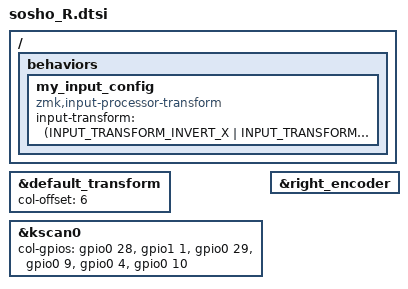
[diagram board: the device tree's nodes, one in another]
#include "sosho.dtsi"
#include <dt-bindings/zmk/input_transform.h>
#include <input/processors.dtsi>

&default_transform {
    col-offset = <6>;
};

&kscan0 {
    col-gpios
        = <&gpio0 28 GPIO_ACTIVE_HIGH>
        , <&gpio1 1  GPIO_ACTIVE_HIGH> 
        , <&gpio0 29 GPIO_ACTIVE_HIGH> 
        , <&gpio0 9  GPIO_ACTIVE_HIGH> 
        , <&gpio0 4  GPIO_ACTIVE_HIGH>
        , <&gpio0 10 GPIO_ACTIVE_HIGH>
        ;
};

&right_encoder{
    status =  "okay";
};

/ {
    behaviors {
        // オートマウスレイヤーの定義などに zip_xy_transform を適用
        my_input_config: my_input_config {
            compatible = "zmk,input-processor-transform";
            #input-processor-cells = <0>;
            // XとYの両方を反転させる場合は以下のように bitwise OR で指定
            input-transform = <(INPUT_TRANSFORM_INVERT_X | INPUT_TRANSFORM_INVERT_Y)>;
        };
    };
};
